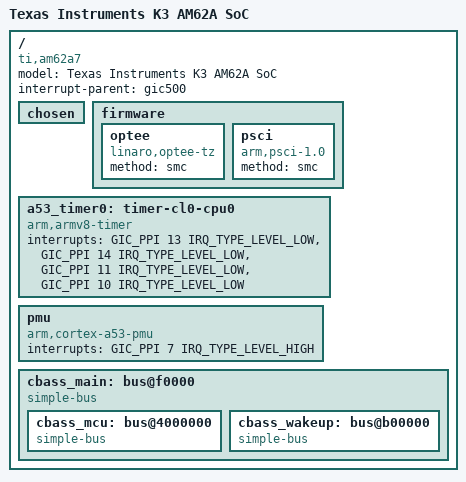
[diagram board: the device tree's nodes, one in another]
#include <dt-bindings/gpio/gpio.h>
#include <dt-bindings/interrupt-controller/irq.h>
#include <dt-bindings/interrupt-controller/arm-gic.h>
#include <dt-bindings/soc/ti,sci_pm_domain.h>
#include "k3-pinctrl.h"
/ {
	model = "Texas Instruments K3 AM62A SoC";
	compatible = "ti,am62a7";
	interrupt-parent = <&gic500>;
	#address-cells = <2>;
	#size-cells = <2>;
	chosen { };
	firmware {
		optee {
			compatible = "linaro,optee-tz";
			method = "smc";
		};
		psci: psci {
			compatible = "arm,psci-1.0";
			method = "smc";
		};
	};
	a53_timer0: timer-cl0-cpu0 {
		compatible = "arm,armv8-timer";
		interrupts = <GIC_PPI 13 IRQ_TYPE_LEVEL_LOW>,  
			     <GIC_PPI 14 IRQ_TYPE_LEVEL_LOW>,  
			     <GIC_PPI 11 IRQ_TYPE_LEVEL_LOW>,  
			     <GIC_PPI 10 IRQ_TYPE_LEVEL_LOW>;  
	};
	pmu: pmu {
		compatible = "arm,cortex-a53-pmu";
		interrupts = <GIC_PPI 7 IRQ_TYPE_LEVEL_HIGH>;
	};
	cbass_main: bus@f0000 {
		compatible = "simple-bus";
		#address-cells = <2>;
		#size-cells = <2>;
		ranges = <0x00 0x000f0000 0x00 0x000f0000 0x00 0x00030000>,  
			 <0x00 0x00420000 0x00 0x00420000 0x00 0x00001000>,  
			 <0x00 0x00600000 0x00 0x00600000 0x00 0x00001100>,  
			 <0x00 0x00703000 0x00 0x00703000 0x00 0x00000200>,  
			 <0x00 0x0070c000 0x00 0x0070c000 0x00 0x00000200>,  
			 <0x00 0x00a40000 0x00 0x00a40000 0x00 0x00000800>,  
			 <0x00 0x01000000 0x00 0x01000000 0x00 0x01b28400>,  
			 <0x00 0x08000000 0x00 0x08000000 0x00 0x00200000>,  
			 <0x00 0x0e000000 0x00 0x0e000000 0x00 0x01d20000>,  
			 <0x00 0x0fd00000 0x00 0x0fd00000 0x00 0x00020000>,  
			 <0x00 0x20000000 0x00 0x20000000 0x00 0x0a008000>,  
			 <0x00 0x30040000 0x00 0x30040000 0x00 0x00080000>,  
			 <0x00 0x30101000 0x00 0x30101000 0x00 0x00010100>,  
			 <0x00 0x30200000 0x00 0x30200000 0x00 0x00010000>,  
			 <0x00 0x30210000 0x00 0x30210000 0x00 0x00010000>,  
			 <0x00 0x31000000 0x00 0x31000000 0x00 0x00050000>,  
			 <0x00 0x31100000 0x00 0x31100000 0x00 0x00050000>,  
			 <0x00 0x40900000 0x00 0x40900000 0x00 0x00030000>,  
			 <0x00 0x43600000 0x00 0x43600000 0x00 0x00010000>,  
			 <0x00 0x44043000 0x00 0x44043000 0x00 0x00000fe0>,  
			 <0x00 0x44860000 0x00 0x44860000 0x00 0x00040000>,  
			 <0x00 0x48000000 0x00 0x48000000 0x00 0x06400000>,  
			 <0x00 0x60000000 0x00 0x60000000 0x00 0x08000000>,  
			 <0x00 0x70000000 0x00 0x70000000 0x00 0x00010000>,  
			 <0x00 0x7e000000 0x00 0x7e000000 0x00 0x00100000>,  
			 <0x01 0x00000000 0x01 0x00000000 0x00 0x00310000>,  
			 <0x05 0x00000000 0x05 0x00000000 0x01 0x00000000>,  
			 <0x00 0x04000000 0x00 0x04000000 0x00 0x01ff1400>,
			 <0x00 0x79000000 0x00 0x79000000 0x00 0x00008000>,  
			 <0x00 0x79020000 0x00 0x79020000 0x00 0x00008000>,  
			 <0x00 0x79100000 0x00 0x79100000 0x00 0x00040000>,  
			 <0x00 0x79140000 0x00 0x79140000 0x00 0x00040000>,  
			 <0x00 0x00b00000 0x00 0x00b00000 0x00 0x00002400>,
			 <0x00 0x2b000000 0x00 0x2b000000 0x00 0x00300400>,
			 <0x00 0x43000000 0x00 0x43000000 0x00 0x00020000>,
			 <0x00 0x78000000 0x00 0x78000000 0x00 0x00008000>,  
			 <0x00 0x78100000 0x00 0x78100000 0x00 0x00008000>;  
		cbass_mcu: bus@4000000 {
			compatible = "simple-bus";
			#address-cells = <2>;
			#size-cells = <2>;
			ranges = <0x00 0x04000000 0x00 0x04000000 0x00 0x01ff1400>,  
				 <0x00 0x79000000 0x00 0x79000000 0x00 0x00008000>,  
				 <0x00 0x79020000 0x00 0x79020000 0x00 0x00008000>,  
				 <0x00 0x79100000 0x00 0x79100000 0x00 0x00040000>,  
				 <0x00 0x79140000 0x00 0x79140000 0x00 0x00040000>;  
		};
		cbass_wakeup: bus@b00000 {
			compatible = "simple-bus";
			#address-cells = <2>;
			#size-cells = <2>;
			ranges = <0x00 0x00b00000 0x00 0x00b00000 0x00 0x00002400>,  
				 <0x00 0x2b000000 0x00 0x2b000000 0x00 0x00300400>,  
				 <0x00 0x43000000 0x00 0x43000000 0x00 0x00020000>,  
				 <0x00 0x78000000 0x00 0x78000000 0x00 0x00008000>,  
				 <0x00 0x78100000 0x00 0x78100000 0x00 0x00008000>;  
		};
	};
	#include "k3-am62a-thermal.dtsi"
};
#include "k3-am62a-main.dtsi"
#include "k3-am62a-mcu.dtsi"
#include "k3-am62a-wakeup.dtsi"
